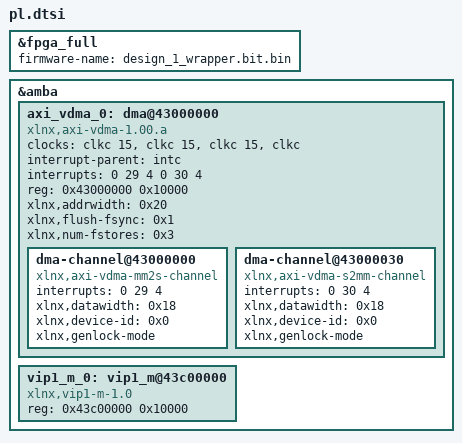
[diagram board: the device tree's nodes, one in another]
/*
 * CAUTION: This file is automatically generated by Xilinx.
 * Version:  
 * Today is: Sat Feb 13 23:01:48 2021
 */


/dts-v1/;
/plugin/;
/ {
	fragment@0 {
		target = <&fpga_full>;
		overlay0: __overlay__ {
			#address-cells = <1>;
			#size-cells = <1>;
			firmware-name = "design_1_wrapper.bit.bin";
		};
	};
	fragment@1 {
		target = <&amba>;
		overlay1: __overlay__ {
			axi_vdma_0: dma@43000000 {
				#dma-cells = <1>;
				clock-names = "s_axi_lite_aclk m_axi_mm2s_aclk m_axi_mm2s_aclk m_axi_s2mm_aclk m_axi_s2mm_aclk";
				clocks = "clkc 15>, <&clkc 15>, <&clkc 15>, <&clkc 15>, <&clkc 15";
				compatible = "xlnx,axi-vdma-1.00.a";
				interrupt-parent = <&intc>;
				interrupts = <0 29 4 0 30 4>;
				reg = <0x43000000 0x10000>;
				xlnx,addrwidth = <0x20>;
				xlnx,flush-fsync = <0x1>;
				xlnx,num-fstores = <0x3>;
				dma-channel@43000000 {
					compatible = "xlnx,axi-vdma-mm2s-channel";
					interrupts = <0 29 4>;
					xlnx,datawidth = <0x18>;
					xlnx,device-id = <0x0>;
					xlnx,genlock-mode ;
				};
				dma-channel@43000030 {
					compatible = "xlnx,axi-vdma-s2mm-channel";
					interrupts = <0 30 4>;
					xlnx,datawidth = <0x18>;
					xlnx,device-id = <0x0>;
					xlnx,genlock-mode ;
				};
			};
			vip1_m_0: vip1_m@43c00000 {
				compatible = "xlnx,vip1-m-1.0";
				reg = <0x43c00000 0x10000>;
			};
		};
	};
};
